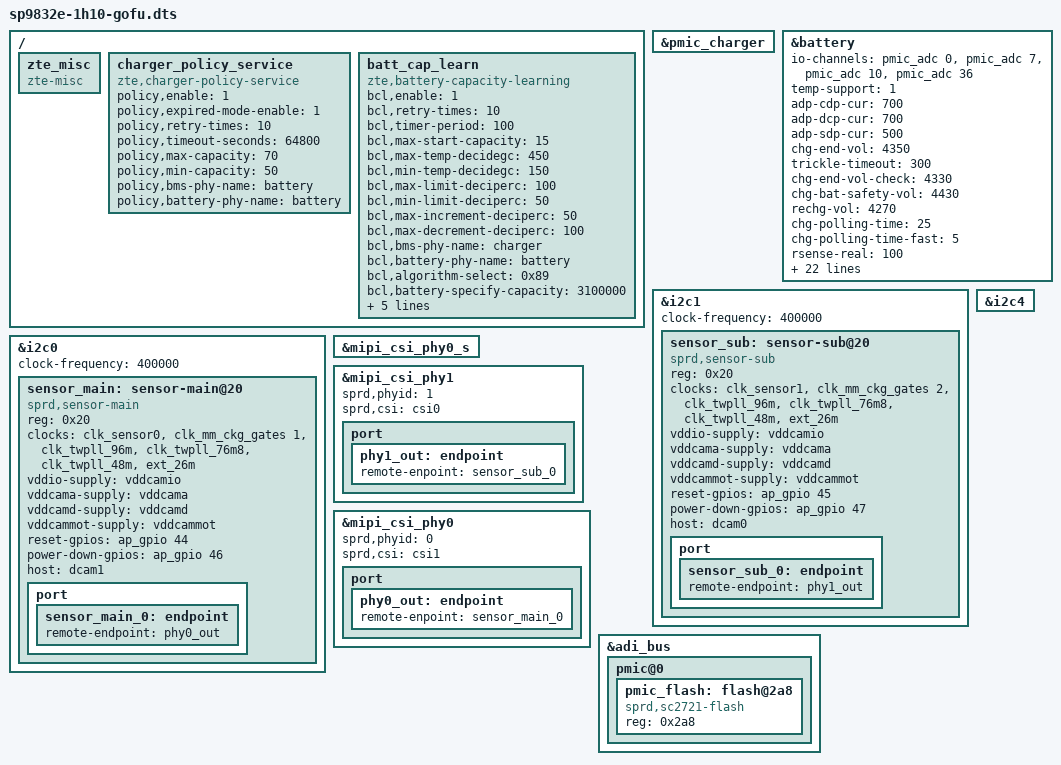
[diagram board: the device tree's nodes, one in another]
/*****************************************
Do not modify dts file, please modify according dtsi file
******************************************/

#include "../sp9832e-1h10-gofu.dts"
#include "sprd_base_diff.dtsi"

/ {
	zte_misc: zte_misc {
		status = "okay";
		compatible = "zte-misc";
	};

	charger_policy_service {
		compatible = "zte,charger-policy-service";
		status="okay";
		policy,enable = <1>;
		policy,expired-mode-enable = <1>;
		policy,retry-times = <10>;
		policy,timeout-seconds = <64800>;/* 18 hours */
		policy,max-capacity = <70>;
		policy,min-capacity = <50>;
		policy,bms-phy-name = "battery";
		policy,battery-phy-name = "battery";
	};

	batt_cap_learn {
		compatible = "zte,battery-capacity-learning";
		bcl,enable = <1>;
		bcl,retry-times = <10>;
		bcl,timer-period = <100>;/*ms*/
		bcl,max-start-capacity = <15>;
		bcl,max-temp-decidegc = <450>;
		bcl,min-temp-decidegc = <150>;
		bcl,max-limit-deciperc = <100>;
		bcl,min-limit-deciperc = <50>;
		bcl,max-increment-deciperc = <50>;
		bcl,max-decrement-deciperc = <100>;
		bcl,bms-phy-name = "charger";
		bcl,battery-phy-name = "battery";
		/*bit7: 0: use zte algorithm calc age; 1: use platform algorithm calc age*/
		/*bit4: enable zte algorithm*/
		/*bit3: enable platform algorithm*/
		/*bit0: platform algorithm mode 0: integral mode; 1: delta mode*/
		bcl,algorithm-select = <0x89>;
		bcl,battery-specify-capacity = <3100000>;
		bcl,battery-specify-voltage = <4390>;

		/*3.4V-3.0V 0.2C delta capacity*/
		/*age 150ma 768ma(0.2C) 1300ma*/
		bcl,disch-curr-volt-prop = <100 64 193 393
						86 82 258 412>;

		/*current: 0.04C - 0.02C delta*/
		bcl,topoff-prop = <100 50
				86 72 >;

		/*reduc voltage  50mv 100mv*/
		bcl,reduc-volt-prop = <100 193 366
					86 230 396 >;
	};
};

&pmic_charger {
	status = "okay";
};

&battery {
	io-channels = <&pmic_adc 0>,<&pmic_adc 7>,<&pmic_adc 10>,
			<&pmic_adc 36>;
	io-channel-names = "adc_batt_id","adc_temp","adc_vbat",
			"adc_vchg";
	temp-support = <1>;
	adp-cdp-cur = <700>;
	adp-dcp-cur = <700>;
	adp-sdp-cur = <500>;
	chg-end-vol = <4350>;
	trickle-timeout = <300>;
	chg-end-vol-check = <4330>;
	chg-bat-safety-vol = <4430>;
	rechg-vol = <4270>;
	chg-polling-time = <25>;
	chg-polling-time-fast = <5>;
	rsense-real = <100>;
	bat-id-list = <47 270>; /* battery id kohm fenghua:47K weike:270K */
	rint = <278>;
	cnom = <2092>;
	ocv-tab-vol = <4321 4245 4184 4128 4076 4022 3977
			3938 3895 3849 3817 3796 3782 3775
			3772 3760 3740 3709 3618 3539 3500>;
	rint-1 = <183>;
	cnom-1 = <2030>;
	ocv-tab-vol-1 = <4326 4254 4195 4140 4088 4041 3986
			3949 3906 3861 3830 3807 3791 3779
			3772 3758 3742 3722 3692 3628 3500>;
	ocv-tab-cap = <100  95   90   85   80   75   70
			65   60   55   50   45   40   35
			30   25   20   15   10   5    0>;
	/*30mohm,if temp-table-mode = <1>, use it*/
	temp-comp-res = <30>;
	temp-tab-val = <1124 1104 1079 1047 1010 967
			917 861 801 738 672 607
			543 482 425 372 325 282 243>;
	/* temperature + 1000,750 = 1000 + (-250)*/
	temp-tab-temp = <750 800 850 900 950 1000
			1050 1100 1150 1200 1250 1300
			1350 1400 1450 1500 1550 1600 1650>;
	jeita-temp-tab = <1000 1050 1150 1450 1550>;
	jeita-temp-recovery-tab = <1030 1080 1180 1420 1520>;
	jeita-cur-tab = <0 600 600 0x7FFF 650 0>;
	jeita-cccv-tab = <4350 4350 4350 4350 4100 4100>;
	batt_full_design_capacity = <2000>;
};

&i2c1 {
	/delete-node/ sensor-sub@20;
};

&i2c0 {
	/delete-node/ sensor-main@20;
};

&mipi_csi_phy0_s {
	/delete-node/ port;
};

&mipi_csi_phy1 {
	/delete-node/ port;
};

&i2c0 {
	status = "okay";
	clock-frequency = <400000>;

	sensor_main: sensor-main@20 {
		compatible = "sprd,sensor-main";
		reg = <0x20>;
		clock-names = "clk_src","sensor_eb",
			"clk_96m","clk_76m8",
			"clk_48m","clk_26m";
		clocks = <&clk_sensor0>, <&clk_mm_ckg_gates 1>,
			<&clk_twpll_96m>,<&clk_twpll_76m8>,
			<&clk_twpll_48m>,<&ext_26m>;
		vddio-supply = <&vddcamio>;
		vddcama-supply = <&vddcama>;
		vddcamd-supply = <&vddcamd>;
		vddcammot-supply = <&vddcammot>;
		reset-gpios = <&ap_gpio 44 0>;
		power-down-gpios = <&ap_gpio 46 0>;
		host = "dcam1";
		port {
			sensor_main_0: endpoint {
				remote-endpoint = <&phy0_out>;
			};
		};
	};
};

&i2c1 {
	status = "okay";
	clock-frequency = <400000>;

	sensor_sub: sensor-sub@20 {
		compatible = "sprd,sensor-sub";
		reg = <0x20>;
		clock-names = "clk_src","sensor_eb",
				"clk_96m","clk_76m8",
				"clk_48m","clk_26m";
		clocks = <&clk_sensor1>, <&clk_mm_ckg_gates 2>,
			<&clk_twpll_96m>,<&clk_twpll_76m8>,
			<&clk_twpll_48m>,<&ext_26m>;
		vddio-supply = <&vddcamio>;
		vddcama-supply = <&vddcama>;
		vddcamd-supply = <&vddcamd>;
		vddcammot-supply = <&vddcammot>;
		reset-gpios = <&ap_gpio 45 0>;
		power-down-gpios = <&ap_gpio 47 0>;
		host = "dcam0";
		port {
			sensor_sub_0: endpoint {
				remote-endpoint = <&phy1_out>;
			};
		};
	};
};

&mipi_csi_phy1 {
	status = "okay";
	sprd,phyid = <1>;
	sprd,csi = <&csi0>;
	port {
	phy1_out: endpoint {
			remote-enpoint = <&sensor_sub_0>;
		};
	};
};

&mipi_csi_phy0 {
	status = "okay";
	sprd,phyid = <0>;
	sprd,csi = <&csi1>;
	port {
		phy0_out: endpoint {
			remote-enpoint = <&sensor_main_0>;
		};
	};
};

&i2c4 {
	/delete-node/ flash-ic@63;
};

&adi_bus {
	pmic@0 {
		/delete-node/ flash@2a8;
	};
	pmic@0 {
		pmic_flash: flash@2a8 {
					compatible = "sprd,sc2721-flash";
					reg=<0x2a8>;
					status = "okay";
					};
		};
};



&pmic_flash {
	compatible = "sprd,sc2721-flash";
	reg=<0x2a8>;
};

